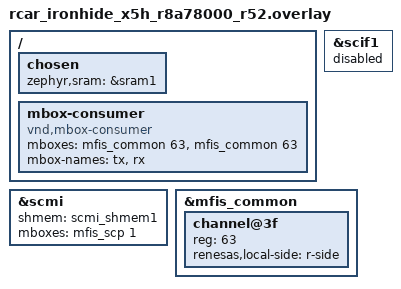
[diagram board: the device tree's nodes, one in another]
/*
 * Copyright (c) 2026 Renesas Electronics Corporation
 * SPDX-License-Identifier: Apache-2.0
 */

/ {
	chosen {
		zephyr,sram = &sram1;
	};

	mbox-consumer {
		compatible = "vnd,mbox-consumer";
		mboxes = <&mfis_common 63>, <&mfis_common 63>;
		mbox-names = "tx", "rx";
	};
};

&scif1 {
	status = "disabled";
};

&scmi {
	shmem = <&scmi_shmem1>;
	mboxes = <&mfis_scp 1>;
};

&mfis_common {
	status = "okay";

	channel@3f {
		reg = <63>;
		renesas,local-side = "r-side";
	};
};
